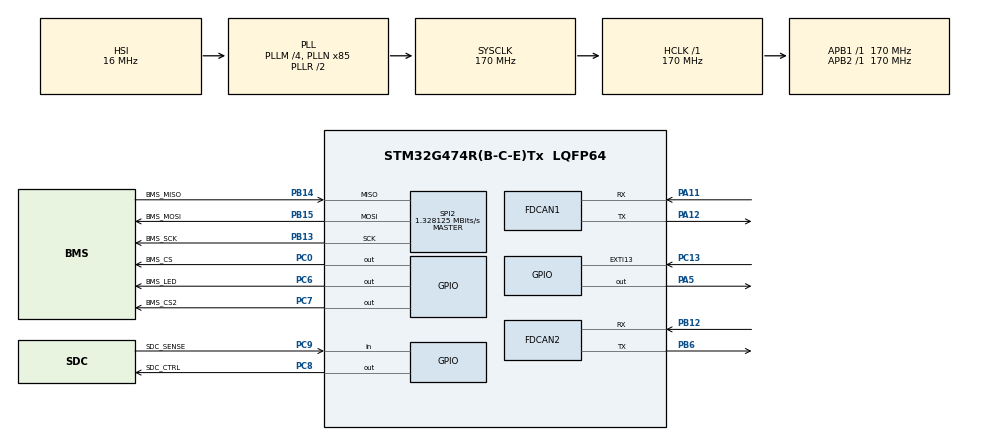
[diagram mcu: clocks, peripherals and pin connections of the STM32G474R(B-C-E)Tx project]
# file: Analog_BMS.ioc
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FDCAN1.CalculateBaudRateNominal=3541666
FDCAN1.CalculateTimeBitNominal=282
FDCAN1.CalculateTimeQuantumNominal=94.11764705882354
FDCAN2.CalculateBaudRateNominal=3541666
FDCAN2.CalculateTimeBitNominal=282
FDCAN2.CalculateTimeQuantumNominal=94.11764705882354
Mcu.Family=STM32G4
Mcu.Name=STM32G474R(B-C-E)Tx
Mcu.Package=LQFP64
NUCLEO-G474RE.BUTTON=1
NUCLEO-G474RE.LD2=true
NUCLEO-G474RE.VCP=true
NVIC.EXTI15_10_IRQn=true\:0\:0\:false\:false\:true\:true\:true\:true
NVIC.PriorityGroup=NVIC_PRIORITYGROUP_4
PA11.Mode=FDCAN_Activate
PA11.Signal=FDCAN1_RX
PA12.Mode=FDCAN_Activate
PA12.Signal=FDCAN1_TX
PA13.GPIO_Label=T_SWDIO
PA13.Signal=SYS_JTMS-SWDIO
PA14.GPIO_Label=T_SWCLK
PA14.Signal=SYS_JTCK-SWCLK
PA2.Signal=LPUART1_TX
PA3.Signal=LPUART1_RX
PA5.Signal=GPIO_Output
PB12.Mode=FDCAN_Activate
PB12.Signal=FDCAN2_RX
PB13.GPIO_Label=BMS_SCK
PB13.Mode=Full_Duplex_Master
PB13.Signal=SPI2_SCK
PB14.GPIO_Label=BMS_MISO
PB14.Mode=Full_Duplex_Master
PB14.Signal=SPI2_MISO
PB15.GPIO_Label=BMS_MOSI
PB15.Mode=Full_Duplex_Master
PB15.Signal=SPI2_MOSI
PB3.GPIO_Label=T_SWO
PB3.Signal=SYS_JTDO-SWO
PB6.Mode=FDCAN_Activate
PB6.Signal=FDCAN2_TX
PC0.GPIO_Label=BMS_CS
PC0.Signal=GPIO_Output
PC13.Signal=GPXTI13
PC14-OSC32_IN.GPIO_Label=RCC_OSC32_IN
PC14-OSC32_IN.Signal=RCC_OSC32_IN
PC15-OSC32_OUT.GPIO_Label=RCC_OSC32_OUT
PC15-OSC32_OUT.Signal=RCC_OSC32_OUT
PC6.GPIO_Label=BMS_LED
PC6.Signal=GPIO_Output
PC7.GPIO_Label=BMS_CS2
PC7.Signal=GPIO_Output
PC8.GPIO_Label=SDC_CTRL
PC8.Signal=GPIO_Output
PC9.GPIO_Label=SDC_SENSE
PC9.GPIO_PuPd=GPIO_PULLDOWN
PC9.Signal=GPIO_Input
PF0-OSC_IN.GPIO_Label=RCC_OSC_IN
PF0-OSC_IN.Signal=RCC_OSC_IN
PF1-OSC_OUT.GPIO_Label=RCC_OSC_OUT
PF1-OSC_OUT.Signal=RCC_OSC_OUT
ProjectManager.HeapSize=0x200
ProjectManager.StackSize=0x400
ProjectManager.TargetToolchain=STM32CubeIDE
RCC.ADC12Freq_Value=170000000
RCC.ADC345Freq_Value=170000000
RCC.AHBFreq_Value=170000000
RCC.APB1Freq_Value=170000000
RCC.APB1TimFreq_Value=170000000
RCC.APB2Freq_Value=170000000
RCC.APB2TimFreq_Value=170000000
RCC.CortexFreq_Value=170000000
RCC.EXTERNAL_CLOCK_VALUE=12288000
RCC.HCLKFreq_Value=170000000
RCC.HSE_VALUE=24000000
RCC.HSI48_VALUE=48000000
RCC.HSI_VALUE=16000000
RCC.LSE_VALUE=32768
RCC.PLLM=RCC_PLLM_DIV4
RCC.PLLN=85
RCC.RTCClockSelection=RCC_RTCCLKSOURCE_LSE
RCC.SYSCLKFreq_VALUE=170000000
RCC.SYSCLKSource=RCC_SYSCLKSOURCE_PLLCLK
RCC.USBFreq_Value=170000000
RCC.VCOOutputFreq_Value=340000000
SPI2.BaudRatePrescaler=SPI_BAUDRATEPRESCALER_128
SPI2.CalculateBaudRate=1.328125 MBits/s
SPI2.DataSize=SPI_DATASIZE_8BIT
SPI2.Direction=SPI_DIRECTION_2LINES
SPI2.Mode=SPI_MODE_MASTER
SPI2.VirtualType=VM_MASTER
TIM2.Prescaler=170-1
VP_NUCLEO-G474RE_VS_BSP_COMMON.Mode=COMMON
VP_SYS_VS_DBSignals.Mode=DisableDeadBatterySignals
VP_TIM2_VS_ClockSourceINT.Mode=Internal
board=NUCLEO-G474RE

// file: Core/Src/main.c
/* USER CODE BEGIN Header */
/**
  ******************************************************************************
  * @file           : main.c
  * @brief          : Main program body
  ******************************************************************************
  * @attention
  *
  * Copyright (c) 2025 STMicroelectronics.
  * All rights reserved.
  *
  * This software is licensed under terms that can be found in the LICENSE file
  * in the root directory of this software component.
  * If no LICENSE file comes with this software, it is provided AS-IS.
  *
  ******************************************************************************
  */
/* USER CODE END Header */
#include "main.h"

/* USER CODE BEGIN Includes */
#include "communication.h"   /* bms_init(), programLoop() -- Analog_libs/inc
                                 já está no include path do projeto (.cproject) */
/* USER CODE END Includes */

COM_InitTypeDef BspCOMInit;
FDCAN_HandleTypeDef hfdcan1;
FDCAN_HandleTypeDef hfdcan2;

SPI_HandleTypeDef hspi2;

TIM_HandleTypeDef htim2;

void SystemClock_Config(void);
static void MX_GPIO_Init(void);
static void MX_SPI2_Init(void);
static void MX_FDCAN1_Init(void);
static void MX_FDCAN2_Init(void);
static void MX_TIM2_Init(void);

int main(void)
{

  /* MCU Configuration--------------------------------------------------------*/

  /* Reset of all peripherals, Initializes the Flash interface and the Systick. */
  HAL_Init();

  /* Configure the system clock */
  SystemClock_Config();

  /* Initialize all configured peripherals */
  MX_GPIO_Init();
  MX_SPI2_Init();
  MX_FDCAN1_Init();
  MX_FDCAN2_Init();
  MX_TIM2_Init();
  /* USER CODE BEGIN 2 */
  if (bms_init() != BMS_OK)
  {
    bms_safety_trigger_shutdown(BMS_FAULT_COMMS);   /* SDC aberto + luz BMS */
    Error_Handler();
  }
  /* USER CODE END 2 */

  /* Initialize led */
  BSP_LED_Init(LED_GREEN);

  /* Initialize USER push-button, will be used to trigger an interrupt each time it's pressed.*/
  BSP_PB_Init(BUTTON_USER, BUTTON_MODE_EXTI);

  /* Initialize COM1 port (115200, 8 bits (7-bit data + 1 stop bit), no parity */
  BspCOMInit.BaudRate   = 115200;
  BspCOMInit.WordLength = COM_WORDLENGTH_8B;
  BspCOMInit.StopBits   = COM_STOPBITS_1;
  BspCOMInit.Parity     = COM_PARITY_NONE;
  BspCOMInit.HwFlowCtl  = COM_HWCONTROL_NONE;
  if (BSP_COM_Init(COM1, &BspCOMInit) != BSP_ERROR_NONE)
  {
    Error_Handler();
  }

  /* Infinite loop */
  /* USER CODE BEGIN WHILE */
  while (1)
  {
    programLoop();
    /* USER CODE END WHILE */

  }
}

void SystemClock_Config(void)
{
  RCC_OscInitTypeDef RCC_OscInitStruct = {0};
  RCC_ClkInitTypeDef RCC_ClkInitStruct = {0};

  /** Configure the main internal regulator output voltage
  */
  HAL_PWREx_ControlVoltageScaling(PWR_REGULATOR_VOLTAGE_SCALE1_BOOST);

  /** Initializes the RCC Oscillators according to the specified parameters
  * in the RCC_OscInitTypeDef structure.
  */
  RCC_OscInitStruct.OscillatorType = RCC_OSCILLATORTYPE_HSI;
  RCC_OscInitStruct.HSIState = RCC_HSI_ON;
  RCC_OscInitStruct.HSICalibrationValue = RCC_HSICALIBRATION_DEFAULT;
  RCC_OscInitStruct.PLL.PLLState = RCC_PLL_ON;
  RCC_OscInitStruct.PLL.PLLSource = RCC_PLLSOURCE_HSI;
  RCC_OscInitStruct.PLL.PLLM = RCC_PLLM_DIV4;
  RCC_OscInitStruct.PLL.PLLN = 85;
  RCC_OscInitStruct.PLL.PLLP = RCC_PLLP_DIV2;
  RCC_OscInitStruct.PLL.PLLQ = RCC_PLLQ_DIV2;
  RCC_OscInitStruct.PLL.PLLR = RCC_PLLR_DIV2;
  if (HAL_RCC_OscConfig(&RCC_OscInitStruct) != HAL_OK)
  {
    Error_Handler();
  }

  /** Initializes the CPU, AHB and APB buses clocks
  */
  RCC_ClkInitStruct.ClockType = RCC_CLOCKTYPE_HCLK|RCC_CLOCKTYPE_SYSCLK
                              |RCC_CLOCKTYPE_PCLK1|RCC_CLOCKTYPE_PCLK2;
  RCC_ClkInitStruct.SYSCLKSource = RCC_SYSCLKSOURCE_PLLCLK;
  RCC_ClkInitStruct.AHBCLKDivider = RCC_SYSCLK_DIV1;
  RCC_ClkInitStruct.APB1CLKDivider = RCC_HCLK_DIV1;
  RCC_ClkInitStruct.APB2CLKDivider = RCC_HCLK_DIV1;

  if (HAL_RCC_ClockConfig(&RCC_ClkInitStruct, FLASH_LATENCY_4) != HAL_OK)
  {
    Error_Handler();
  }
}

static void MX_FDCAN1_Init(void)
{

  hfdcan1.Instance = FDCAN1;
  hfdcan1.Init.ClockDivider = FDCAN_CLOCK_DIV1;
  hfdcan1.Init.FrameFormat = FDCAN_FRAME_CLASSIC;
  hfdcan1.Init.Mode = FDCAN_MODE_NORMAL;
  hfdcan1.Init.AutoRetransmission = DISABLE;
  hfdcan1.Init.TransmitPause = DISABLE;
  hfdcan1.Init.ProtocolException = DISABLE;
  hfdcan1.Init.NominalPrescaler = 16;
  hfdcan1.Init.NominalSyncJumpWidth = 1;
  hfdcan1.Init.NominalTimeSeg1 = 1;
  hfdcan1.Init.NominalTimeSeg2 = 1;
  hfdcan1.Init.DataPrescaler = 1;
  hfdcan1.Init.DataSyncJumpWidth = 1;
  hfdcan1.Init.DataTimeSeg1 = 1;
  hfdcan1.Init.DataTimeSeg2 = 1;
  hfdcan1.Init.StdFiltersNbr = 0;
  hfdcan1.Init.ExtFiltersNbr = 0;
  hfdcan1.Init.TxFifoQueueMode = FDCAN_TX_FIFO_OPERATION;
  if (HAL_FDCAN_Init(&hfdcan1) != HAL_OK)
  {
    Error_Handler();
  }

}

static void MX_FDCAN2_Init(void)
{

  hfdcan2.Instance = FDCAN2;
  hfdcan2.Init.ClockDivider = FDCAN_CLOCK_DIV1;
  hfdcan2.Init.FrameFormat = FDCAN_FRAME_CLASSIC;
  hfdcan2.Init.Mode = FDCAN_MODE_NORMAL;
  hfdcan2.Init.AutoRetransmission = DISABLE;
  hfdcan2.Init.TransmitPause = DISABLE;
  hfdcan2.Init.ProtocolException = DISABLE;
  hfdcan2.Init.NominalPrescaler = 16;
  hfdcan2.Init.NominalSyncJumpWidth = 1;
  hfdcan2.Init.NominalTimeSeg1 = 1;
  hfdcan2.Init.NominalTimeSeg2 = 1;
  hfdcan2.Init.DataPrescaler = 1;
  hfdcan2.Init.DataSyncJumpWidth = 1;
  hfdcan2.Init.DataTimeSeg1 = 1;
  hfdcan2.Init.DataTimeSeg2 = 1;
  hfdcan2.Init.StdFiltersNbr = 0;
  hfdcan2.Init.ExtFiltersNbr = 0;
  hfdcan2.Init.TxFifoQueueMode = FDCAN_TX_FIFO_OPERATION;
  if (HAL_FDCAN_Init(&hfdcan2) != HAL_OK)
  {
    Error_Handler();
  }

}

static void MX_SPI2_Init(void)
{

  /* SPI2 parameter configuration*/
  hspi2.Instance = SPI2;
  hspi2.Init.Mode = SPI_MODE_MASTER;
  hspi2.Init.Direction = SPI_DIRECTION_2LINES;
  hspi2.Init.DataSize = SPI_DATASIZE_8BIT;
  hspi2.Init.CLKPolarity = SPI_POLARITY_LOW;
  hspi2.Init.CLKPhase = SPI_PHASE_1EDGE;
  hspi2.Init.NSS = SPI_NSS_SOFT;
  hspi2.Init.BaudRatePrescaler = SPI_BAUDRATEPRESCALER_128;
  hspi2.Init.FirstBit = SPI_FIRSTBIT_MSB;
  hspi2.Init.TIMode = SPI_TIMODE_DISABLE;
  hspi2.Init.CRCCalculation = SPI_CRCCALCULATION_DISABLE;
  hspi2.Init.CRCPolynomial = 7;
  hspi2.Init.CRCLength = SPI_CRC_LENGTH_DATASIZE;
  hspi2.Init.NSSPMode = SPI_NSS_PULSE_ENABLE;
  if (HAL_SPI_Init(&hspi2) != HAL_OK)
  {
    Error_Handler();
  }

}

static void MX_TIM2_Init(void)
{

  TIM_ClockConfigTypeDef sClockSourceConfig = {0};
  TIM_MasterConfigTypeDef sMasterConfig = {0};

  htim2.Instance = TIM2;
  htim2.Init.Prescaler = 170-1;
  htim2.Init.CounterMode = TIM_COUNTERMODE_UP;
  htim2.Init.Period = 4294967295;
  htim2.Init.ClockDivision = TIM_CLOCKDIVISION_DIV1;
  htim2.Init.AutoReloadPreload = TIM_AUTORELOAD_PRELOAD_DISABLE;
  if (HAL_TIM_Base_Init(&htim2) != HAL_OK)
  {
    Error_Handler();
  }
  sClockSourceConfig.ClockSource = TIM_CLOCKSOURCE_INTERNAL;
  if (HAL_TIM_ConfigClockSource(&htim2, &sClockSourceConfig) != HAL_OK)
  {
    Error_Handler();
  }
  sMasterConfig.MasterOutputTrigger = TIM_TRGO_RESET;
  sMasterConfig.MasterSlaveMode = TIM_MASTERSLAVEMODE_DISABLE;
  if (HAL_TIMEx_MasterConfigSynchronization(&htim2, &sMasterConfig) != HAL_OK)
  {
    Error_Handler();
  }

}

static void MX_GPIO_Init(void)
{
  GPIO_InitTypeDef GPIO_InitStruct = {0};

  /* GPIO Ports Clock Enable */
  __HAL_RCC_GPIOC_CLK_ENABLE();
  __HAL_RCC_GPIOF_CLK_ENABLE();
  __HAL_RCC_GPIOB_CLK_ENABLE();
  __HAL_RCC_GPIOA_CLK_ENABLE();

  /*Configure GPIO pin Output Level */
  HAL_GPIO_WritePin(GPIOC, BMS_CS_Pin|BMS_CS2_Pin|BMS_LED_Pin|SDC_CTRL_Pin, GPIO_PIN_RESET);

  /*Configure GPIO pins : BMS_CS_Pin BMS_CS2_Pin BMS_LED_Pin SDC_CTRL_Pin */
  GPIO_InitStruct.Pin = BMS_CS_Pin|BMS_CS2_Pin|BMS_LED_Pin|SDC_CTRL_Pin;
  GPIO_InitStruct.Mode = GPIO_MODE_OUTPUT_PP;
  GPIO_InitStruct.Pull = GPIO_NOPULL;
  GPIO_InitStruct.Speed = GPIO_SPEED_FREQ_LOW;
  HAL_GPIO_Init(GPIOC, &GPIO_InitStruct);

  /*Configure GPIO pin : SDC_SENSE_Pin */
  GPIO_InitStruct.Pin = SDC_SENSE_Pin;
  GPIO_InitStruct.Mode = GPIO_MODE_INPUT;
  GPIO_InitStruct.Pull = GPIO_PULLDOWN;
  HAL_GPIO_Init(SDC_SENSE_GPIO_Port, &GPIO_InitStruct);

}

void Error_Handler(void)
{
  __disable_irq();
  while (1)
  {
  }
}
